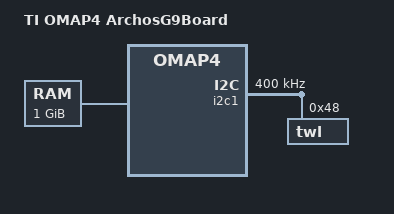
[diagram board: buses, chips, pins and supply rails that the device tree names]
/dts-v1/;

/include/ "omap4.dtsi"

/ {
	model = "TI OMAP4 ArchosG9Board";
	compatible = "ti,archos_a80s", "ti,omap4460", "ti,omap4";

	memory {
		device_type = "memory";
		reg = <0x80000000 0x40000000>; /* 1 GB */
	};
};

&i2c1 {
	clock-frequency = <400000>;

	twl: twl@48 {
		reg = <0x48>;
		/* SPI = 0, IRQ# = 7, 4 = active high level-sensitive */
		interrupts = <0 7 4>; /* IRQ_SYS_1N cascaded to gic */
		interrupt-parent = <&gic>;
	};
};

/* /include/ "twl6030.dtsi" */ /* Not included in 3.4 release */
